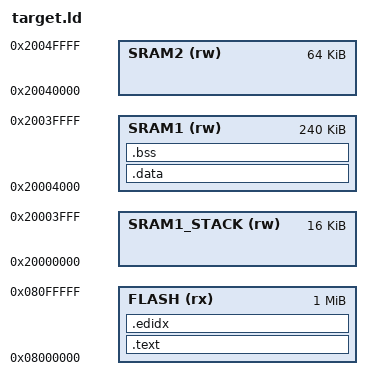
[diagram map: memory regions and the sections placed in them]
/* target.ld
 *
 * Copyright (C) 2006-2023 wolfSSL Inc.
 *
 * This file is part of wolfSSL.
 *
 * wolfSSL is free software; you can redistribute it and/or modify
 * it under the terms of the GNU General Public License as published by
 * the Free Software Foundation; either version 2 of the License, or
 * (at your option) any later version.
 *
 * wolfSSL is distributed in the hope that it will be useful,
 * but WITHOUT ANY WARRANTY; without even the implied warranty of
 * MERCHANTABILITY or FITNESS FOR A PARTICULAR PURPOSE.  See the
 * GNU General Public License for more details.
 *
 * You should have received a copy of the GNU General Public License
 * along with this program; if not, write to the Free Software
 * Foundation, Inc., 51 Franklin Street, Fifth Floor, Boston, MA 02110-1335, USA
 */

/* IoT-safe example
 * Linker script for STM32L4
 */


MEMORY
{
    FLASH (rx) : ORIGIN = 0x08000000, LENGTH = 1M
    SRAM1_STACK (rw) : ORIGIN = 0x20000000, LENGTH = 16K
    SRAM1(rw) : ORIGIN = 0x20000000 + 16K, LENGTH = 256K - 16K
    SRAM2 (rw) : ORIGIN = 0x20040000, LENGTH = 64K
}

SECTIONS
{
    .text :
    {
        _start_text = .;
        KEEP(*(.isr_vector))
        *(.text*)
        *(.rodata*)
        . = ALIGN(4);
        _end_text = .;
    } > FLASH

    .edidx :
    {
        . = ALIGN(4);
        *(.ARM.exidx*)
    } > FLASH

    _stored_data = .;

    .data : AT (_stored_data)
    {
        _start_data = .;
        *(.data*)
        . = ALIGN(4);
        _end_data = .;
    } > SRAM1

    .bss :
    {
        _start_bss = .;
        *(.bss*)
        *(COMMON)
        . = ALIGN(4);
        _end_bss = .;
        _end = .;
    } > SRAM1 

}

PROVIDE(_start_heap = ORIGIN(SRAM2));
PROVIDE(_end_stack  = ORIGIN(SRAM1_STACK) + LENGTH(SRAM1_STACK));
